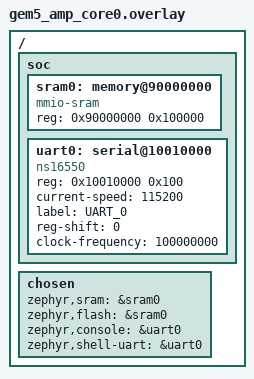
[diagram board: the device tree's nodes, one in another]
/ {
    soc {
        sram0: memory@90000000 {
            compatible = "mmio-sram";
            reg = <0x90000000 0x100000>;
        };
    };

    chosen {
        zephyr,sram = &sram0;
        zephyr,flash = &sram0;
        zephyr,console = &uart0;
        zephyr,shell-uart = &uart0;
    };
};

/ {
    soc {
        uart0: serial@10010000 {
            compatible = "ns16550";
            reg = <0x10010000 0x100>;
            status = "okay";
            current-speed = <115200>;
            label = "UART_0";
            reg-shift = <0>;
            clock-frequency = <100000000>;
        };
    };
};



